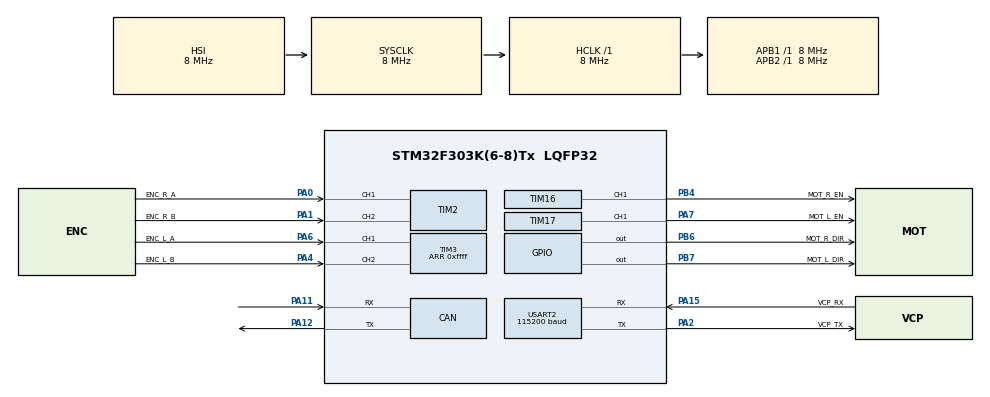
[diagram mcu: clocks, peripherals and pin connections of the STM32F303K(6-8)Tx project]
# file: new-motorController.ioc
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CAN.CalculateTimeBit=6000
CAN.CalculateTimeQuantum=2000.0
Mcu.Family=STM32F3
Mcu.Name=STM32F303K(6-8)Tx
Mcu.Package=LQFP32
NVIC.PriorityGroup=NVIC_PRIORITYGROUP_4
NVIC.USART2_IRQn=true\:0\:0\:false\:true\:true\:1
PA0.GPIO_Label=ENC_R_A
PA0.Signal=S_TIM2_CH1_ETR
PA1.GPIO_Label=ENC_R_B
PA1.Signal=S_TIM2_CH2
PA11.Mode=Master
PA11.Signal=CAN_RX
PA12.Mode=Master
PA12.Signal=CAN_TX
PA13.GPIO_Label=SWDIO
PA13.Signal=SYS_JTMS-SWDIO
PA14.GPIO_Label=SWCLK
PA14.Signal=SYS_JTCK-SWCLK
PA15.GPIO_Label=VCP_RX
PA15.Mode=Asynchronous
PA15.Signal=USART2_RX
PA2.GPIO_Label=VCP_TX
PA2.Mode=Asynchronous
PA2.Signal=USART2_TX
PA4.GPIO_Label=ENC_L_B
PA4.Signal=S_TIM3_CH2
PA6.GPIO_Label=ENC_L_A
PA6.Signal=S_TIM3_CH1
PA7.GPIO_Label=MOT_L_EN
PA7.Signal=S_TIM17_CH1
PB4.GPIO_Label=MOT_R_EN
PB4.Signal=S_TIM16_CH1
PB6.GPIO_Label=MOT_R_DIR
PB6.Signal=GPIO_Output
PB7.GPIO_Label=MOT_L_DIR
PB7.Signal=GPIO_Output
PF0\ /\ OSC_IN.GPIO_Label=MCO
PF0\ /\ OSC_IN.Signal=RCC_OSC_IN
ProjectManager.HeapSize=0x200
ProjectManager.StackSize=0x400
ProjectManager.TargetToolchain=SW4STM32
RCC.AHBFreq_Value=8000000
RCC.APB1Freq_Value=8000000
RCC.APB2Freq_Value=8000000
RCC.CortexFreq_Value=8000000
RCC.HSE_VALUE=8000000
RCC.HSI_VALUE=8000000
RCC.SYSCLKFreq_VALUE=8000000
SH.S_TIM16_CH1.0=TIM16_CH1,PWM Generation1 CH1
SH.S_TIM17_CH1.0=TIM17_CH1,PWM Generation1 CH1
SH.S_TIM2_CH1_ETR.0=TIM2_CH1,Encoder_Interface
SH.S_TIM2_CH2.0=TIM2_CH2,Encoder_Interface
SH.S_TIM3_CH1.0=TIM3_CH1,Encoder_Interface
SH.S_TIM3_CH2.0=TIM3_CH2,Encoder_Interface
TIM3.EncoderMode=TIM_ENCODERMODE_TI12
TIM3.Period=0xffff
USART2.BaudRate=115200
USART2.WordLength=UART_WORDLENGTH_8B
VP_TIM16_VS_ClockSourceINT.Mode=Enable_Timer
VP_TIM17_VS_ClockSourceINT.Mode=Enable_Timer
board=NUCLEO-F303K8

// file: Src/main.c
/**
  ******************************************************************************
  * File Name          : main.c
  * Description        : Main program body
  ******************************************************************************
  *
  * COPYRIGHT(c) 2018 STMicroelectronics
  *
  * Redistribution and use in source and binary forms, with or without modification,
  * are permitted provided that the following conditions are met:
  *   1. Redistributions of source code must retain the above copyright notice,
  *      this list of conditions and the following disclaimer.
  *   2. Redistributions in binary form must reproduce the above copyright notice,
  *      this list of conditions and the following disclaimer in the documentation
  *      and/or other materials provided with the distribution.
  *   3. Neither the name of STMicroelectronics nor the names of its contributors
  *      may be used to endorse or promote products derived from this software
  *      without specific prior written permission.
  *
  * THIS SOFTWARE IS PROVIDED BY THE COPYRIGHT HOLDERS AND CONTRIBUTORS "AS IS"
  * AND ANY EXPRESS OR IMPLIED WARRANTIES, INCLUDING, BUT NOT LIMITED TO, THE
  * IMPLIED WARRANTIES OF MERCHANTABILITY AND FITNESS FOR A PARTICULAR PURPOSE ARE
  * DISCLAIMED. IN NO EVENT SHALL THE COPYRIGHT HOLDER OR CONTRIBUTORS BE LIABLE
  * FOR ANY DIRECT, INDIRECT, INCIDENTAL, SPECIAL, EXEMPLARY, OR CONSEQUENTIAL
  * DAMAGES (INCLUDING, BUT NOT LIMITED TO, PROCUREMENT OF SUBSTITUTE GOODS OR
  * SERVICES; LOSS OF USE, DATA, OR PROFITS; OR BUSINESS INTERRUPTION) HOWEVER
  * CAUSED AND ON ANY THEORY OF LIABILITY, WHETHER IN CONTRACT, STRICT LIABILITY,
  * OR TORT (INCLUDING NEGLIGENCE OR OTHERWISE) ARISING IN ANY WAY OUT OF THE USE
  * OF THIS SOFTWARE, EVEN IF ADVISED OF THE POSSIBILITY OF SUCH DAMAGE.
  *
  ******************************************************************************
  */
#include "stm32f3xx_hal.h"

/* USER CODE BEGIN Includes */
#include "motionController.h"
/* USER CODE END Includes */

CAN_HandleTypeDef hcan;

TIM_HandleTypeDef htim2;
TIM_HandleTypeDef htim3;
TIM_HandleTypeDef htim16;
TIM_HandleTypeDef htim17;

UART_HandleTypeDef huart2;

/* USER CODE BEGIN PV */
/* Private variables ---------------------------------------------------------*/

/* USER CODE END PV */

void SystemClock_Config(void);
void Error_Handler(void);
static void MX_GPIO_Init(void);
static void MX_CAN_Init(void);
static void MX_TIM2_Init(void);
static void MX_TIM3_Init(void);
static void MX_TIM16_Init(void);
static void MX_TIM17_Init(void);
static void MX_USART2_UART_Init(void);
static void MX_NVIC_Init(void);

void HAL_TIM_MspPostInit(TIM_HandleTypeDef *htim);

/* USER CODE BEGIN PFP */
/* Private function prototypes -----------------------------------------------*/

/* USER CODE END PFP */

int main(void)
{

  /* MCU Configuration----------------------------------------------------------*/

  /* Reset of all peripherals, Initializes the Flash interface and the Systick. */
  HAL_Init();

  /* Configure the system clock */
  SystemClock_Config();

  /* Initialize all configured peripherals */
  MX_GPIO_Init();
  MX_CAN_Init();
  MX_TIM2_Init();
  MX_TIM3_Init();
  MX_TIM16_Init();
  MX_TIM17_Init();
  MX_USART2_UART_Init();

  /* Initialize interrupts */
  MX_NVIC_Init();

  /* USER CODE BEGIN 2 */
  motionController_init(&huart2, &hcan, &htim2, &htim3, &htim16, &htim17);
  /* USER CODE END 2 */

  /* Infinite loop */
  while (1)
  {

  }

}

/** System Clock Configuration
*/
void SystemClock_Config(void)
{

  RCC_OscInitTypeDef RCC_OscInitStruct;
  RCC_ClkInitTypeDef RCC_ClkInitStruct;

  RCC_OscInitStruct.OscillatorType = RCC_OSCILLATORTYPE_HSI;
  RCC_OscInitStruct.HSIState = RCC_HSI_ON;
  RCC_OscInitStruct.HSICalibrationValue = 16;
  RCC_OscInitStruct.PLL.PLLState = RCC_PLL_NONE;
  if (HAL_RCC_OscConfig(&RCC_OscInitStruct) != HAL_OK)
  {
    Error_Handler();
  }

  RCC_ClkInitStruct.ClockType = RCC_CLOCKTYPE_HCLK|RCC_CLOCKTYPE_SYSCLK
                              |RCC_CLOCKTYPE_PCLK1|RCC_CLOCKTYPE_PCLK2;
  RCC_ClkInitStruct.SYSCLKSource = RCC_SYSCLKSOURCE_HSI;
  RCC_ClkInitStruct.AHBCLKDivider = RCC_SYSCLK_DIV1;
  RCC_ClkInitStruct.APB1CLKDivider = RCC_HCLK_DIV1;
  RCC_ClkInitStruct.APB2CLKDivider = RCC_HCLK_DIV1;
  if (HAL_RCC_ClockConfig(&RCC_ClkInitStruct, FLASH_LATENCY_0) != HAL_OK)
  {
    Error_Handler();
  }

  HAL_SYSTICK_Config(HAL_RCC_GetHCLKFreq()/1000);

  HAL_SYSTICK_CLKSourceConfig(SYSTICK_CLKSOURCE_HCLK);

  /* SysTick_IRQn interrupt configuration */
  HAL_NVIC_SetPriority(SysTick_IRQn, 0, 0);
}

/** NVIC Configuration
*/
static void MX_NVIC_Init(void)
{
  /* USART2_IRQn interrupt configuration */
  HAL_NVIC_SetPriority(USART2_IRQn, 0, 0);
  HAL_NVIC_EnableIRQ(USART2_IRQn);
}

/* CAN init function */
static void MX_CAN_Init(void)
{

  hcan.Instance = CAN;
  hcan.Init.Prescaler = 16;
  hcan.Init.Mode = CAN_MODE_NORMAL;
  hcan.Init.SJW = CAN_SJW_1TQ;
  hcan.Init.BS1 = CAN_BS1_1TQ;
  hcan.Init.BS2 = CAN_BS2_1TQ;
  hcan.Init.TTCM = DISABLE;
  hcan.Init.ABOM = DISABLE;
  hcan.Init.AWUM = DISABLE;
  hcan.Init.NART = DISABLE;
  hcan.Init.RFLM = DISABLE;
  hcan.Init.TXFP = DISABLE;
  if (HAL_CAN_Init(&hcan) != HAL_OK)
  {
    Error_Handler();
  }

}

/* TIM2 init function */
static void MX_TIM2_Init(void)
{

  TIM_Encoder_InitTypeDef sConfig;
  TIM_MasterConfigTypeDef sMasterConfig;

  htim2.Instance = TIM2;
  htim2.Init.Prescaler = 0;
  htim2.Init.CounterMode = TIM_COUNTERMODE_UP;
  htim2.Init.Period = 0;
  htim2.Init.ClockDivision = TIM_CLOCKDIVISION_DIV1;
  sConfig.EncoderMode = TIM_ENCODERMODE_TI1;
  sConfig.IC1Polarity = TIM_ICPOLARITY_RISING;
  sConfig.IC1Selection = TIM_ICSELECTION_DIRECTTI;
  sConfig.IC1Prescaler = TIM_ICPSC_DIV1;
  sConfig.IC1Filter = 0;
  sConfig.IC2Polarity = TIM_ICPOLARITY_RISING;
  sConfig.IC2Selection = TIM_ICSELECTION_DIRECTTI;
  sConfig.IC2Prescaler = TIM_ICPSC_DIV1;
  sConfig.IC2Filter = 0;
  if (HAL_TIM_Encoder_Init(&htim2, &sConfig) != HAL_OK)
  {
    Error_Handler();
  }

  sMasterConfig.MasterOutputTrigger = TIM_TRGO_RESET;
  sMasterConfig.MasterSlaveMode = TIM_MASTERSLAVEMODE_DISABLE;
  if (HAL_TIMEx_MasterConfigSynchronization(&htim2, &sMasterConfig) != HAL_OK)
  {
    Error_Handler();
  }

}

/* TIM3 init function */
static void MX_TIM3_Init(void)
{

  TIM_Encoder_InitTypeDef sConfig;
  TIM_MasterConfigTypeDef sMasterConfig;

  htim3.Instance = TIM3;
  htim3.Init.Prescaler = 0;
  htim3.Init.CounterMode = TIM_COUNTERMODE_UP;
  htim3.Init.Period = 0xffff;
  htim3.Init.ClockDivision = TIM_CLOCKDIVISION_DIV1;
  sConfig.EncoderMode = TIM_ENCODERMODE_TI12;
  sConfig.IC1Polarity = TIM_ICPOLARITY_RISING;
  sConfig.IC1Selection = TIM_ICSELECTION_DIRECTTI;
  sConfig.IC1Prescaler = TIM_ICPSC_DIV1;
  sConfig.IC1Filter = 0;
  sConfig.IC2Polarity = TIM_ICPOLARITY_RISING;
  sConfig.IC2Selection = TIM_ICSELECTION_DIRECTTI;
  sConfig.IC2Prescaler = TIM_ICPSC_DIV1;
  sConfig.IC2Filter = 0;
  if (HAL_TIM_Encoder_Init(&htim3, &sConfig) != HAL_OK)
  {
    Error_Handler();
  }

  sMasterConfig.MasterOutputTrigger = TIM_TRGO_RESET;
  sMasterConfig.MasterSlaveMode = TIM_MASTERSLAVEMODE_DISABLE;
  if (HAL_TIMEx_MasterConfigSynchronization(&htim3, &sMasterConfig) != HAL_OK)
  {
    Error_Handler();
  }

}

/* TIM16 init function */
static void MX_TIM16_Init(void)
{

  TIM_BreakDeadTimeConfigTypeDef sBreakDeadTimeConfig;
  TIM_OC_InitTypeDef sConfigOC;

  htim16.Instance = TIM16;
  htim16.Init.Prescaler = 0;
  htim16.Init.CounterMode = TIM_COUNTERMODE_UP;
  htim16.Init.Period = 0;
  htim16.Init.ClockDivision = TIM_CLOCKDIVISION_DIV1;
  htim16.Init.RepetitionCounter = 0;
  if (HAL_TIM_Base_Init(&htim16) != HAL_OK)
  {
    Error_Handler();
  }

  if (HAL_TIM_PWM_Init(&htim16) != HAL_OK)
  {
    Error_Handler();
  }

  sBreakDeadTimeConfig.OffStateRunMode = TIM_OSSR_DISABLE;
  sBreakDeadTimeConfig.OffStateIDLEMode = TIM_OSSI_DISABLE;
  sBreakDeadTimeConfig.LockLevel = TIM_LOCKLEVEL_OFF;
  sBreakDeadTimeConfig.DeadTime = 0;
  sBreakDeadTimeConfig.BreakState = TIM_BREAK_DISABLE;
  sBreakDeadTimeConfig.BreakPolarity = TIM_BREAKPOLARITY_HIGH;
  sBreakDeadTimeConfig.BreakFilter = 0;
  sBreakDeadTimeConfig.AutomaticOutput = TIM_AUTOMATICOUTPUT_DISABLE;
  if (HAL_TIMEx_ConfigBreakDeadTime(&htim16, &sBreakDeadTimeConfig) != HAL_OK)
  {
    Error_Handler();
  }

  sConfigOC.OCMode = TIM_OCMODE_PWM1;
  sConfigOC.Pulse = 0;
  sConfigOC.OCPolarity = TIM_OCPOLARITY_HIGH;
  sConfigOC.OCNPolarity = TIM_OCNPOLARITY_HIGH;
  sConfigOC.OCFastMode = TIM_OCFAST_DISABLE;
  sConfigOC.OCIdleState = TIM_OCIDLESTATE_RESET;
  sConfigOC.OCNIdleState = TIM_OCNIDLESTATE_RESET;
  if (HAL_TIM_PWM_ConfigChannel(&htim16, &sConfigOC, TIM_CHANNEL_1) != HAL_OK)
  {
    Error_Handler();
  }

  HAL_TIM_MspPostInit(&htim16);

}

/* TIM17 init function */
static void MX_TIM17_Init(void)
{

  TIM_BreakDeadTimeConfigTypeDef sBreakDeadTimeConfig;
  TIM_OC_InitTypeDef sConfigOC;

  htim17.Instance = TIM17;
  htim17.Init.Prescaler = 0;
  htim17.Init.CounterMode = TIM_COUNTERMODE_UP;
  htim17.Init.Period = 0;
  htim17.Init.ClockDivision = TIM_CLOCKDIVISION_DIV1;
  htim17.Init.RepetitionCounter = 0;
  if (HAL_TIM_Base_Init(&htim17) != HAL_OK)
  {
    Error_Handler();
  }

  if (HAL_TIM_PWM_Init(&htim17) != HAL_OK)
  {
    Error_Handler();
  }

  sBreakDeadTimeConfig.OffStateRunMode = TIM_OSSR_DISABLE;
  sBreakDeadTimeConfig.OffStateIDLEMode = TIM_OSSI_DISABLE;
  sBreakDeadTimeConfig.LockLevel = TIM_LOCKLEVEL_OFF;
  sBreakDeadTimeConfig.DeadTime = 0;
  sBreakDeadTimeConfig.BreakState = TIM_BREAK_DISABLE;
  sBreakDeadTimeConfig.BreakPolarity = TIM_BREAKPOLARITY_HIGH;
  sBreakDeadTimeConfig.BreakFilter = 0;
  sBreakDeadTimeConfig.AutomaticOutput = TIM_AUTOMATICOUTPUT_DISABLE;
  if (HAL_TIMEx_ConfigBreakDeadTime(&htim17, &sBreakDeadTimeConfig) != HAL_OK)
  {
    Error_Handler();
  }

  sConfigOC.OCMode = TIM_OCMODE_PWM1;
  sConfigOC.Pulse = 0;
  sConfigOC.OCPolarity = TIM_OCPOLARITY_HIGH;
  sConfigOC.OCNPolarity = TIM_OCNPOLARITY_HIGH;
  sConfigOC.OCFastMode = TIM_OCFAST_DISABLE;
  sConfigOC.OCIdleState = TIM_OCIDLESTATE_RESET;
  sConfigOC.OCNIdleState = TIM_OCNIDLESTATE_RESET;
  if (HAL_TIM_PWM_ConfigChannel(&htim17, &sConfigOC, TIM_CHANNEL_1) != HAL_OK)
  {
    Error_Handler();
  }

  HAL_TIM_MspPostInit(&htim17);

}

/* USART2 init function */
static void MX_USART2_UART_Init(void)
{

  huart2.Instance = USART2;
  huart2.Init.BaudRate = 115200;
  huart2.Init.WordLength = UART_WORDLENGTH_8B;
  huart2.Init.StopBits = UART_STOPBITS_1;
  huart2.Init.Parity = UART_PARITY_NONE;
  huart2.Init.Mode = UART_MODE_TX_RX;
  huart2.Init.HwFlowCtl = UART_HWCONTROL_NONE;
  huart2.Init.OverSampling = UART_OVERSAMPLING_16;
  huart2.Init.OneBitSampling = UART_ONE_BIT_SAMPLE_DISABLE;
  huart2.AdvancedInit.AdvFeatureInit = UART_ADVFEATURE_NO_INIT;
  if (HAL_UART_Init(&huart2) != HAL_OK)
  {
    Error_Handler();
  }

}

/** Configure pins as
        * Analog
        * Input
        * Output
        * EVENT_OUT
        * EXTI
*/
static void MX_GPIO_Init(void)
{

  GPIO_InitTypeDef GPIO_InitStruct;

  /* GPIO Ports Clock Enable */
  __HAL_RCC_GPIOF_CLK_ENABLE();
  __HAL_RCC_GPIOA_CLK_ENABLE();
  __HAL_RCC_GPIOB_CLK_ENABLE();

  /*Configure GPIO pin Output Level */
  HAL_GPIO_WritePin(GPIOB, MOT_R_DIR_Pin|MOT_L_DIR_Pin, GPIO_PIN_RESET);

  /*Configure GPIO pins : MOT_R_DIR_Pin MOT_L_DIR_Pin */
  GPIO_InitStruct.Pin = MOT_R_DIR_Pin|MOT_L_DIR_Pin;
  GPIO_InitStruct.Mode = GPIO_MODE_OUTPUT_PP;
  GPIO_InitStruct.Pull = GPIO_NOPULL;
  GPIO_InitStruct.Speed = GPIO_SPEED_FREQ_LOW;
  HAL_GPIO_Init(GPIOB, &GPIO_InitStruct);

}

void Error_Handler(void)
{
  while(1)
  {
  }
}

/************************ (C) COPYRIGHT STMicroelectronics *****END OF FILE****/
